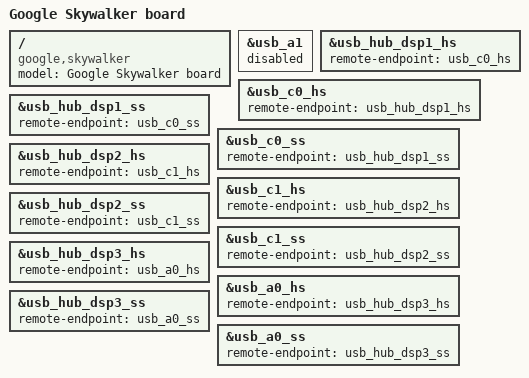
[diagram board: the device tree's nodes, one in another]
// SPDX-License-Identifier: (GPL-2.0 OR MIT)
/*
 * Copyright (C) 2025 Google Inc.
 */
/dts-v1/;
#include "mt8189-skywalker.dtsi"

/ {
	model = "Google Skywalker board";
	compatible = "google,skywalker", "mediatek,mt8189";
};

&usb_a1 {
	status = "disabled";
};

/* USB hub port 1 */
&usb_hub_dsp1_hs {
	remote-endpoint = <&usb_c0_hs>;
};

&usb_c0_hs {
	remote-endpoint = <&usb_hub_dsp1_hs>;
};

&usb_hub_dsp1_ss {
	remote-endpoint = <&usb_c0_ss>;
};

&usb_c0_ss {
	remote-endpoint = <&usb_hub_dsp1_ss>;
};

/* USB hub port 2 */
&usb_hub_dsp2_hs {
	remote-endpoint = <&usb_c1_hs>;
};

&usb_c1_hs {
	remote-endpoint = <&usb_hub_dsp2_hs>;
};

&usb_hub_dsp2_ss {
	remote-endpoint = <&usb_c1_ss>;
};

&usb_c1_ss {
	remote-endpoint = <&usb_hub_dsp2_ss>;
};

/* USB hub port 3 */
&usb_hub_dsp3_hs {
	remote-endpoint = <&usb_a0_hs>;
};

&usb_a0_hs {
	remote-endpoint = <&usb_hub_dsp3_hs>;
};

&usb_hub_dsp3_ss {
	remote-endpoint = <&usb_a0_ss>;
};

&usb_a0_ss {
	remote-endpoint = <&usb_hub_dsp3_ss>;
};

/* USB hub port 4 is for on-board WWAN card */
